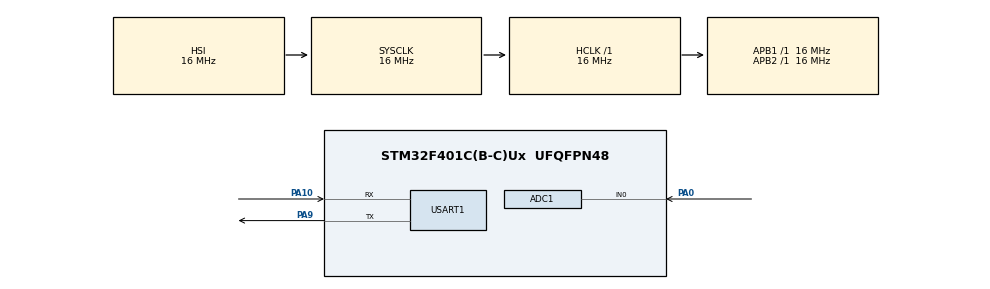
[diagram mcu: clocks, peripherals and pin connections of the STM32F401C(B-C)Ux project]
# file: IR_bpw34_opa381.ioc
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ADC1.Channel-0\#ChannelRegularConversion=ADC_CHANNEL_0
ADC1.NbrOfConversionFlag=1
ADC1.Rank-0\#ChannelRegularConversion=1
ADC1.SamplingTime-0\#ChannelRegularConversion=ADC_SAMPLETIME_3CYCLES
ADC1.master=1
FREERTOS.Queues01=Data_Holder,16,int16_t,0,Dynamic,NULL,NULL
FREERTOS.Tasks01=Read_Bpw34,24,128,StartDefaultTask,Default,NULL,Dynamic,NULL,NULL;Send_Bpw34,8,128,StartTask02,Default,NULL,Dynamic,NULL,NULL;Command_Handler,40,128,StartCommandHandler,Default,NULL,Dynamic,NULL,NULL
FREERTOS.configUSE_NEWLIB_REENTRANT=1
Mcu.Family=STM32F4
Mcu.Name=STM32F401C(B-C)Ux
Mcu.Package=UFQFPN48
NVIC.PriorityGroup=NVIC_PRIORITYGROUP_4
NVIC.TIM4_IRQn=true\:15\:0\:false\:false\:true\:false\:false\:true\:true
NVIC.TimeBase=TIM4_IRQn
NVIC.TimeBaseIP=TIM4
NVIC.USART1_IRQn=true\:5\:0\:false\:false\:true\:true\:true\:true\:true
PA0-WKUP.Signal=ADCx_IN0
PA10.Mode=Asynchronous
PA10.Signal=USART1_RX
PA13.Mode=Trace_Asynchronous_SW
PA13.Signal=SYS_JTMS-SWDIO
PA14.Mode=Trace_Asynchronous_SW
PA14.Signal=SYS_JTCK-SWCLK
PA9.Mode=Asynchronous
PA9.Signal=USART1_TX
PB3.Mode=Trace_Asynchronous_SW
PB3.Signal=SYS_JTDO-SWO
ProjectManager.HeapSize=0x200
ProjectManager.StackSize=0x400
ProjectManager.TargetToolchain=STM32CubeIDE
RCC.AHBFreq_Value=16000000
RCC.APB1Freq_Value=16000000
RCC.APB2Freq_Value=16000000
RCC.CortexFreq_Value=16000000
RCC.HSE_VALUE=25000000
RCC.HSI_VALUE=16000000
RCC.LSE_VALUE=32768
RCC.SYSCLKFreq_VALUE=16000000
RCC.VCOOutputFreq_Value=192000000
SH.ADCx_IN0.0=ADC1_IN0,IN0
USART1.VirtualMode=VM_ASYNC
VP_FREERTOS_VS_CMSIS_V2.Mode=CMSIS_V2
VP_SYS_VS_tim4.Mode=TIM4
board=custom

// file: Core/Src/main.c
/* USER CODE BEGIN Header */
/**
  ******************************************************************************
  * @file           : main.c
  * @brief          : Main program body
  ******************************************************************************
  * @attention
  *
  * Copyright (c) 2026 STMicroelectronics.
  * All rights reserved.
  *
  * This software is licensed under terms that can be found in the LICENSE file
  * in the root directory of this software component.
  * If no LICENSE file comes with this software, it is provided AS-IS.
  *
  ******************************************************************************
  */
/* USER CODE END Header */
#include "main.h"
#include "cmsis_os.h"

/* USER CODE BEGIN Includes */
#include <stdio.h>
#include <string.h>
/* USER CODE END Includes */

ADC_HandleTypeDef hadc1;

UART_HandleTypeDef huart1;

/* Definitions for Read_Bpw34 */
osThreadId_t Read_Bpw34Handle;
const osThreadAttr_t Read_Bpw34_attributes = {
  .name = "Read_Bpw34",
  .stack_size = 128 * 4,
  .priority = (osPriority_t) osPriorityNormal,
};
/* Definitions for Send_Bpw34 */
osThreadId_t Send_Bpw34Handle;
const osThreadAttr_t Send_Bpw34_attributes = {
  .name = "Send_Bpw34",
  .stack_size = 128 * 4,
  .priority = (osPriority_t) osPriorityLow,
};
/* Definitions for Command_Handler */
osThreadId_t Command_HandlerHandle;
const osThreadAttr_t Command_Handler_attributes = {
  .name = "Command_Handler",
  .stack_size = 128 * 4,
  .priority = (osPriority_t) osPriorityHigh,
};
/* Definitions for Data_Holder */
osMessageQueueId_t Data_HolderHandle;
const osMessageQueueAttr_t Data_Holder_attributes = {
  .name = "Data_Holder"
};
/* USER CODE BEGIN PV */
static int16_t adc_value = 0;
char uart_buffer[32];

#define UART_RX_BUFFER_SIZE 32
uint8_t rx_buffer[UART_RX_BUFFER_SIZE];
uint8_t rx_data[UART_RX_BUFFER_SIZE];
uint8_t rx_index = 0;
uint8_t command_received = 0;
uint8_t handshake_complete = 0;
uint32_t reading_duration = 0;  // in seconds
uint32_t reading_count = 0;
/* USER CODE END PV */

void SystemClock_Config(void);
static void MX_GPIO_Init(void);
static void MX_ADC1_Init(void);
static void MX_USART1_UART_Init(void);
void StartDefaultTask(void *argument);
void StartTask02(void *argument);
void StartCommandHandler(void *argument);

int main(void)
{

  /* MCU Configuration--------------------------------------------------------*/

  /* Reset of all peripherals, Initializes the Flash interface and the Systick. */
  HAL_Init();

  /* Configure the system clock */
  SystemClock_Config();

  /* Initialize all configured peripherals */
  MX_GPIO_Init();
  MX_ADC1_Init();
  MX_USART1_UART_Init();

  /* Init scheduler */
  osKernelInitialize();

  /* Create the queue(s) */
  /* creation of Data_Holder */
  Data_HolderHandle = osMessageQueueNew (16, sizeof(int16_t), &Data_Holder_attributes);

  /* Create the thread(s) */
  /* creation of Read_Bpw34 */
  Read_Bpw34Handle = osThreadNew(StartDefaultTask, NULL, &Read_Bpw34_attributes);

  /* creation of Send_Bpw34 */
  Send_Bpw34Handle = osThreadNew(StartTask02, NULL, &Send_Bpw34_attributes);

  /* creation of Command_Handler */
  Command_HandlerHandle = osThreadNew(StartCommandHandler, NULL, &Command_Handler_attributes);

  /* Start scheduler */
  osKernelStart();

  /* We should never get here as control is now taken by the scheduler */

  /* Infinite loop */
  while (1)
  {

  }
}

void SystemClock_Config(void)
{
  RCC_OscInitTypeDef RCC_OscInitStruct = {0};
  RCC_ClkInitTypeDef RCC_ClkInitStruct = {0};

  /** Configure the main internal regulator output voltage
  */
  __HAL_RCC_PWR_CLK_ENABLE();
  __HAL_PWR_VOLTAGESCALING_CONFIG(PWR_REGULATOR_VOLTAGE_SCALE2);

  /** Initializes the RCC Oscillators according to the specified parameters
  * in the RCC_OscInitTypeDef structure.
  */
  RCC_OscInitStruct.OscillatorType = RCC_OSCILLATORTYPE_HSI;
  RCC_OscInitStruct.HSIState = RCC_HSI_ON;
  RCC_OscInitStruct.HSICalibrationValue = RCC_HSICALIBRATION_DEFAULT;
  RCC_OscInitStruct.PLL.PLLState = RCC_PLL_NONE;
  if (HAL_RCC_OscConfig(&RCC_OscInitStruct) != HAL_OK)
  {
    Error_Handler();
  }

  /** Initializes the CPU, AHB and APB buses clocks
  */
  RCC_ClkInitStruct.ClockType = RCC_CLOCKTYPE_HCLK|RCC_CLOCKTYPE_SYSCLK
                              |RCC_CLOCKTYPE_PCLK1|RCC_CLOCKTYPE_PCLK2;
  RCC_ClkInitStruct.SYSCLKSource = RCC_SYSCLKSOURCE_HSI;
  RCC_ClkInitStruct.AHBCLKDivider = RCC_SYSCLK_DIV1;
  RCC_ClkInitStruct.APB1CLKDivider = RCC_HCLK_DIV1;
  RCC_ClkInitStruct.APB2CLKDivider = RCC_HCLK_DIV1;

  if (HAL_RCC_ClockConfig(&RCC_ClkInitStruct, FLASH_LATENCY_0) != HAL_OK)
  {
    Error_Handler();
  }
}

static void MX_ADC1_Init(void)
{

  ADC_ChannelConfTypeDef sConfig = {0};

  /** Configure the global features of the ADC (Clock, Resolution, Data Alignment and number of conversion)
  */
  hadc1.Instance = ADC1;
  hadc1.Init.ClockPrescaler = ADC_CLOCK_SYNC_PCLK_DIV2;
  hadc1.Init.Resolution = ADC_RESOLUTION_12B;
  hadc1.Init.ScanConvMode = DISABLE;
  hadc1.Init.ContinuousConvMode = DISABLE;
  hadc1.Init.DiscontinuousConvMode = DISABLE;
  hadc1.Init.ExternalTrigConvEdge = ADC_EXTERNALTRIGCONVEDGE_NONE;
  hadc1.Init.ExternalTrigConv = ADC_SOFTWARE_START;
  hadc1.Init.DataAlign = ADC_DATAALIGN_RIGHT;
  hadc1.Init.NbrOfConversion = 1;
  hadc1.Init.DMAContinuousRequests = DISABLE;
  hadc1.Init.EOCSelection = ADC_EOC_SINGLE_CONV;
  if (HAL_ADC_Init(&hadc1) != HAL_OK)
  {
    Error_Handler();
  }

  /** Configure for the selected ADC regular channel its corresponding rank in the sequencer and its sample time.
  */
  sConfig.Channel = ADC_CHANNEL_0;
  sConfig.Rank = 1;
  sConfig.SamplingTime = ADC_SAMPLETIME_3CYCLES;
  if (HAL_ADC_ConfigChannel(&hadc1, &sConfig) != HAL_OK)
  {
    Error_Handler();
  }

}

static void MX_USART1_UART_Init(void)
{

  huart1.Instance = USART1;
  huart1.Init.BaudRate = 115200;
  huart1.Init.WordLength = UART_WORDLENGTH_8B;
  huart1.Init.StopBits = UART_STOPBITS_1;
  huart1.Init.Parity = UART_PARITY_NONE;
  huart1.Init.Mode = UART_MODE_TX_RX;
  huart1.Init.HwFlowCtl = UART_HWCONTROL_NONE;
  huart1.Init.OverSampling = UART_OVERSAMPLING_16;
  if (HAL_UART_Init(&huart1) != HAL_OK)
  {
    Error_Handler();
  }
  /* USER CODE BEGIN USART1_Init 2 */
  HAL_UART_Receive_IT(&huart1, rx_data, 1);
  /* USER CODE END USART1_Init 2 */

}

static void MX_GPIO_Init(void)
{

  /* GPIO Ports Clock Enable */
  __HAL_RCC_GPIOA_CLK_ENABLE();
  __HAL_RCC_GPIOB_CLK_ENABLE();

}

/* USER CODE BEGIN 4 */
/* USER CODE BEGIN 4 */

void HAL_UART_RxCpltCallback(UART_HandleTypeDef *huart)
{
  if (huart->Instance == USART1)
  {
    // Store received character
    rx_buffer[rx_index++] = rx_data[0];

    // Check for newline or carriage return (end of command)
    if (rx_data[0] == '\n' || rx_data[0] == '\r')
    {
      rx_buffer[rx_index - 1] = '\0';  // Null terminate string
      command_received = 1;
      rx_index = 0;
    }
    else if (rx_index >= UART_RX_BUFFER_SIZE - 1)
    {
      // Buffer overflow, reset
      rx_index = 0;
    }

    // Start next reception
    HAL_UART_Receive_IT(&huart1, rx_data, 1);
  }
}

void HAL_UART_TxCpltCallback(UART_HandleTypeDef *huart)
{
  /* Optional: Handle UART transmit complete */
  if (huart->Instance == USART1)
  {
    /* Set a flag or do something when transmission is complete */
  }
}
/* USER CODE END 4 */

void StartDefaultTask(void *argument)
{
  /* USER CODE BEGIN 5 */
	osStatus_t status;

  /* Infinite loop */
  for(;;)
  {
	  if (reading_duration > 0 && reading_count < reading_duration)
	      {
	        HAL_ADC_Start(&hadc1);

	        if (HAL_ADC_PollForConversion(&hadc1, 100) == HAL_OK)
	        {
	          adc_value = (int16_t)HAL_ADC_GetValue(&hadc1);

	          status = osMessageQueuePut(
	                    Data_HolderHandle,
	                    &adc_value,
	                    0,
	                    0);

	          reading_count++;  // Increment reading count
	        }
	        HAL_ADC_Stop(&hadc1);

	        // Check if we've completed the requested duration
	        if (reading_count >= reading_duration)
	        {
	          char done_msg[] = "READING_COMPLETE\n";
	          HAL_UART_Transmit(&huart1, (uint8_t*)done_msg, strlen(done_msg), 100);
	          reading_duration = 0;  // Reset for next session
	        }
	      }

	  osDelay(1000);
  }
  /* USER CODE END 5 */
}

void StartTask02(void *argument)
{
  /* USER CODE BEGIN StartTask02 */
	int16_t received_value;
    osStatus_t status;
    uint8_t tx_buffer[32];
    int len;
  /* Infinite loop */
  for(;;)
  {
	  status = osMessageQueueGet(Data_HolderHandle, &received_value, NULL, osWaitForever);

	  if (status == osOK && reading_duration > 0){
			/* Option 1: Send as raw binary data (2 bytes) */
			// tx_buffer[0] = (received_value >> 8) & 0xFF;  // High byte
			// tx_buffer[1] = received_value & 0xFF;         // Low byte
			// HAL_UART_Transmit(&huart1, tx_buffer, 2, 100);

			/* Option 2: Send as formatted string (human readable) */
//			len = snprintf((char*)tx_buffer, sizeof(tx_buffer), "ADC: %d\r\n", received_value);
//			HAL_UART_Transmit(&huart1, tx_buffer, len, 100);

			/* Option 3: Send as CSV format for easier parsing */
			 len = snprintf((char*)tx_buffer, sizeof(tx_buffer), "%d\r\n", received_value);
			 HAL_UART_Transmit(&huart1, tx_buffer, len, 100);
	  }

  }
  /* USER CODE END StartTask02 */
}

void StartCommandHandler(void *argument)
{
  /* USER CODE BEGIN StartCommandHandler */

	char cmd_buffer[32];
	uint32_t duration;
  /* Infinite loop */
  for(;;)
  {

	  if (command_received)
	      {
	        command_received = 0;
	        strcpy(cmd_buffer, (char*)rx_buffer);

	        // Check for "PING" command
	        if (strncmp(cmd_buffer, "PING", 4) == 0)
	        {
	          // Send PONG response
	          char response[] = "PONG\n";
	          HAL_UART_Transmit(&huart1, (uint8_t*)response, strlen(response), 100);
	          handshake_complete = 1;
	        }
	        // Check for duration command (format: "DURATION:10" for 10 seconds)
	        else if (strncmp(cmd_buffer, "DURATION:", 9) == 0)
	        {
	          // Parse the duration value
	          duration = atoi(cmd_buffer + 9);
	          if (duration > 0 && duration <= 3600)  // Max 1 hour
	          {
	            reading_duration = duration;
	            reading_count = 0;
	            // Acknowledge the duration command
	            char ack[32];
	            snprintf(ack, sizeof(ack), "ACK:%lu\n", duration);
	            HAL_UART_Transmit(&huart1, (uint8_t*)ack, strlen(ack), 100);
	          }
	          else
	          {
	            char error[] = "ERROR:Invalid duration\n";
	            HAL_UART_Transmit(&huart1, (uint8_t*)error, strlen(error), 100);
	          }
	        }
	        // Check for "START" command
	        else if (strncmp(cmd_buffer, "START", 5) == 0)
	        {
	          if (handshake_complete && reading_duration > 0)
	          {
	            char start_msg[] = "START_READING\n";
	            HAL_UART_Transmit(&huart1, (uint8_t*)start_msg, strlen(start_msg), 100);
	            reading_count = 0;
	          }
	          else
	          {
	            char error[] = "ERROR:Handshake not complete or duration not set\n";
	            HAL_UART_Transmit(&huart1, (uint8_t*)error, strlen(error), 100);
	          }
	        }
	        else if (strncmp(cmd_buffer, "STOP", 4) == 0)
	        {
	          reading_duration = 0;
	          char stop_msg[] = "STOPPED\n";
	          HAL_UART_Transmit(&huart1, (uint8_t*)stop_msg, strlen(stop_msg), 100);
	        }
	        else
	        {
	          char error[] = "ERROR:Unknown command\n";
	          HAL_UART_Transmit(&huart1, (uint8_t*)error, strlen(error), 100);
	        }
	      }
    osDelay(10);
  }
  /* USER CODE END StartCommandHandler */
}

void HAL_TIM_PeriodElapsedCallback(TIM_HandleTypeDef *htim)
{
  if (htim->Instance == TIM4)
  {
    HAL_IncTick();
  }
}

void Error_Handler(void)
{
  __disable_irq();
  while (1)
  {
  }
}
